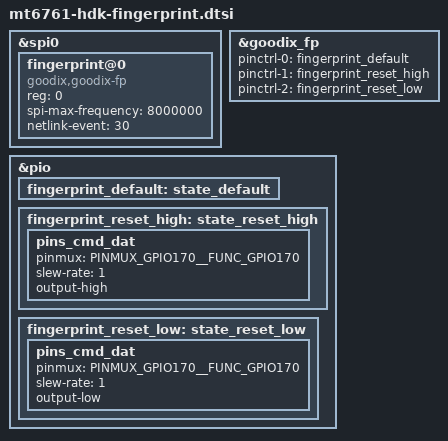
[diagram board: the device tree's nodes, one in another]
/*
 * LG Electronics MT6761 HDK fingerprint device tree source
 *
 * Copyright (c) 2018 LG Electronics Co., Ltd.
 *              http://www.lge.com
 *
 */

/* FINGERPRINT start */
&spi0 {
	#address-cells = <1>;
	#size-cells = <0>;
	fingerprint@0 {
		compatible = "goodix,goodix-fp";
		reg = <0>;
		spi-max-frequency = <8000000>;
		netlink-event = <30>;
		status = "okay";
	};
};

&goodix_fp {
	pinctrl-names = "default", "reset_high", "reset_low";
	pinctrl-0 = <&fingerprint_default>;
	pinctrl-1 = <&fingerprint_reset_high>;
	pinctrl-2 = <&fingerprint_reset_low>;
	status = "okay";
};

&pio {
	fingerprint_default: state_default {
	};
	fingerprint_reset_high: state_reset_high {
		pins_cmd_dat {
			pinmux = <PINMUX_GPIO170__FUNC_GPIO170>;
			slew-rate = <1>;
			output-high;
		};
	};
	fingerprint_reset_low: state_reset_low {
		pins_cmd_dat {
			pinmux = <PINMUX_GPIO170__FUNC_GPIO170>;
			slew-rate = <1>;
			output-low;
		};
	};
};
/* FINGERPRINT end */
